# COMPUTE_CLUSTER0_MSMC_ECC_AGGR0 register map
Vendor: Texas Instruments
Peripheral module from a debugger description file (folder J7ES).
Registers are 32-bit, access not given, reset 0x0 unless marked. A register's access mark holds for its fields unless they carry their own. Offsets are as the file gives them; lines under a group give offsets from that group; [hi:lo] are bit positions; {n}, {i} and the like mark numbered series; 'fields as' and 'values as' point back to an identical list; <NAME> marks a mode.

## COMPUTE_CLUSTER0_MSMC_ECC_AGGR0
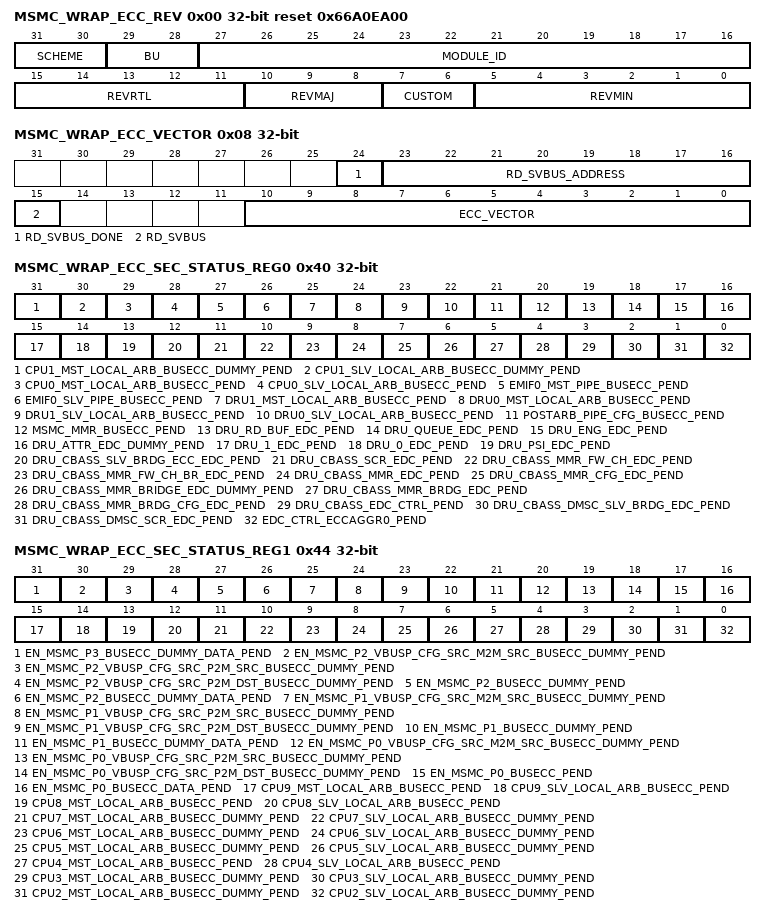
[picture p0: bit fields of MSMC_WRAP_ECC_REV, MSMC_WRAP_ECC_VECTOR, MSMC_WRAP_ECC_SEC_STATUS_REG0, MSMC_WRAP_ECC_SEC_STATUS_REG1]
0x00 MSMC_WRAP_ECC_REV ro reset 0x66A0EA00 — Revision parameters
  [31:30] SCHEME
  [29:28] BU
  [27:16] MODULE_ID
  [15:11] REVRTL — RTL version
  [10:8] REVMAJ — Major version
  [7:6] CUSTOM — Custom version
  [5:0] REVMIN — Minor version
0x08 MSMC_WRAP_ECC_VECTOR — ECC Vector Register
  [24] RD_SVBUS_DONE — Status to indicate if read on serial VBUS is complete, write of any value will clear this bit. (access RW1C)
  [23:16] RD_SVBUS_ADDRESS rw — Read address
  [15] RD_SVBUS — Write 1 to trigger a read on the serial VBUS (access RW1S)
  [10:0] ECC_VECTOR rw — Value written to select the corresponding ECC RAM for control or status
0x0C MSMC_WRAP_ECC_STAT ro reset 0x6C — Misc Status
  [10:0] NUM_RAMS — Indicates the number of RAMS serviced by the ECC aggregator
0x10 MSMC_WRAP_ECC_RESERVED_SVBUS_y rw — Reference other documents that contain the ECC RAM wrapper and EDC controller serial vbus register sets. Offset = 10h + (y * 4h); where y = 0h to 7h
  [31:0] DATA — Serial VBUS register data
0x3C MSMC_WRAP_ECC_SEC_EOI_REG — EOI Register The EOI register is used to re-trigger the pulse interrupt signal to ensure that any nested interrupt events are serviced. The software interrupt handler must write to the EOI register at the end of the current interrupt processing routine, so that new events can re-trigger the pulse interrupt signal again. For level interrupt signals the EOI register is not functional and must not be used.
  [0] EOI_WR — EOI Register (access RW1S)
0x40 MSMC_WRAP_ECC_SEC_STATUS_REG0 — Interrupt Status Register 0
  [31] CPU1_MST_LOCAL_ARB_BUSECC_DUMMY_PEND — Interrupt Pending Status for cpu1_mst_local_arb_busecc_dummy_pend (access RW1S)
  [30] CPU1_SLV_LOCAL_ARB_BUSECC_DUMMY_PEND — Interrupt Pending Status for cpu1_slv_local_arb_busecc_dummy_pend (access RW1S)
  [29] CPU0_MST_LOCAL_ARB_BUSECC_PEND — Interrupt Pending Status for cpu0_mst_local_arb_busecc_pend (access RW1S)
  [28] CPU0_SLV_LOCAL_ARB_BUSECC_PEND — Interrupt Pending Status for cpu0_slv_local_arb_busecc_pend (access RW1S)
  [27] EMIF0_MST_PIPE_BUSECC_PEND — Interrupt Pending Status for emif0_mst_pipe_busecc_pend (access RW1S)
  [26] EMIF0_SLV_PIPE_BUSECC_PEND — Interrupt Pending Status for emif0_slv_pipe_busecc_pend (access RW1S)
  [25] DRU1_MST_LOCAL_ARB_BUSECC_PEND — Interrupt Pending Status for dru1_mst_local_arb_busecc_pend (access RW1S)
  [24] DRU0_MST_LOCAL_ARB_BUSECC_PEND — Interrupt Pending Status for dru0_mst_local_arb_busecc_pend (access RW1S)
  [23] DRU1_SLV_LOCAL_ARB_BUSECC_PEND — Interrupt Pending Status for dru1_slv_local_arb_busecc_pend (access RW1S)
  [22] DRU0_SLV_LOCAL_ARB_BUSECC_PEND — Interrupt Pending Status for dru0_slv_local_arb_busecc_pend (access RW1S)
  [21] POSTARB_PIPE_CFG_BUSECC_PEND — Interrupt Pending Status for postarb_pipe_cfg_busecc_pend (access RW1S)
  [20] MSMC_MMR_BUSECC_PEND — Interrupt Pending Status for msmc_mmr_busecc_pend (access RW1S)
  [19] DRU_RD_BUF_EDC_PEND — Interrupt Pending Status for dru_rd_buf_edc_pend (access RW1S)
  [18] DRU_QUEUE_EDC_PEND — Interrupt Pending Status for dru_queue_edc_pend (access RW1S)
  [17] DRU_ENG_EDC_PEND — Interrupt Pending Status for dru_eng_edc_pend (access RW1S)
  [16] DRU_ATTR_EDC_DUMMY_PEND — Interrupt Pending Status for dru_attr_edc_dummy_pend (access RW1S)
  [15] DRU_1_EDC_PEND — Interrupt Pending Status for dru_1_edc_pend (access RW1S)
  [14] DRU_0_EDC_PEND — Interrupt Pending Status for dru_0_edc_pend (access RW1S)
  [13] DRU_PSI_EDC_PEND — Interrupt Pending Status for dru_psi_edc_pend (access RW1S)
  [12] DRU_CBASS_SLV_BRDG_ECC_EDC_PEND — Interrupt Pending Status for dru_cbass_slv_brdg_ecc_edc_pend (access RW1S)
  [11] DRU_CBASS_SCR_EDC_PEND — Interrupt Pending Status for dru_cbass_scr_edc_pend (access RW1S)
  [10] DRU_CBASS_MMR_FW_CH_EDC_PEND — Interrupt Pending Status for dru_cbass_mmr_fw_ch_edc_pend (access RW1S)
  [9] DRU_CBASS_MMR_FW_CH_BR_EDC_PEND — Interrupt Pending Status for dru_cbass_mmr_fw_ch_br_edc_pend (access RW1S)
  [8] DRU_CBASS_MMR_EDC_PEND — Interrupt Pending Status for dru_cbass_mmr_edc_pend (access RW1S)
  [7] DRU_CBASS_MMR_CFG_EDC_PEND — Interrupt Pending Status for dru_cbass_mmr_cfg_edc_pend (access RW1S)
  [6] DRU_CBASS_MMR_BRIDGE_EDC_DUMMY_PEND — Interrupt Pending Status for dru_cbass_mmr_bridge_edc_dummy_pend (access RW1S)
  [5] DRU_CBASS_MMR_BRDG_EDC_PEND — Interrupt Pending Status for dru_cbass_mmr_brdg_edc_pend (access RW1S)
  [4] DRU_CBASS_MMR_BRDG_CFG_EDC_PEND — Interrupt Pending Status for dru_cbass_mmr_brdg_cfg_edc_pend (access RW1S)
  [3] DRU_CBASS_EDC_CTRL_PEND — Interrupt Pending Status for dru_cbass_edc_ctrl_pend (access RW1S)
  [2] DRU_CBASS_DMSC_SLV_BRDG_EDC_PEND — Interrupt Pending Status for dru_cbass_dmsc_slv_brdg_edc_pend (access RW1S)
  [1] DRU_CBASS_DMSC_SCR_EDC_PEND — Interrupt Pending Status for dru_cbass_dmsc_scr_edc_pend (access RW1S)
  [0] EDC_CTRL_ECCAGGR0_PEND — Interrupt Pending Status for edc_ctrl_eccaggr0_pend (access RW1S)
0x44 MSMC_WRAP_ECC_SEC_STATUS_REG1 — Interrupt Status Register 1
  [31] EN_MSMC_P3_BUSECC_DUMMY_DATA_PEND — Interrupt Pending Status for en_msmc_p3_busecc_dummy_data_pend (access RW1S)
  [30] EN_MSMC_P2_VBUSP_CFG_SRC_M2M_SRC_BUSECC_DUMMY_PEND — Interrupt Pending Status for en_msmc_p2_vbusp_cfg_src_m2m_src_busecc_dummy_pend (access RW1S)
  [29] EN_MSMC_P2_VBUSP_CFG_SRC_P2M_SRC_BUSECC_DUMMY_PEND — Interrupt Pending Status for en_msmc_p2_vbusp_cfg_src_p2m_src_busecc_dummy_pend (access RW1S)
  [28] EN_MSMC_P2_VBUSP_CFG_SRC_P2M_DST_BUSECC_DUMMY_PEND — Interrupt Pending Status for en_msmc_p2_vbusp_cfg_src_p2m_dst_busecc_dummy_pend (access RW1S)
  [27] EN_MSMC_P2_BUSECC_DUMMY_PEND — Interrupt Pending Status for en_msmc_p2_busecc_dummy_pend (access RW1S)
  [26] EN_MSMC_P2_BUSECC_DUMMY_DATA_PEND — Interrupt Pending Status for en_msmc_p2_busecc_dummy_data_pend (access RW1S)
  [25] EN_MSMC_P1_VBUSP_CFG_SRC_M2M_SRC_BUSECC_DUMMY_PEND — Interrupt Pending Status for en_msmc_p1_vbusp_cfg_src_m2m_src_busecc_dummy_pend (access RW1S)
  [24] EN_MSMC_P1_VBUSP_CFG_SRC_P2M_SRC_BUSECC_DUMMY_PEND — Interrupt Pending Status for en_msmc_p1_vbusp_cfg_src_p2m_src_busecc_dummy_pend (access RW1S)
  [23] EN_MSMC_P1_VBUSP_CFG_SRC_P2M_DST_BUSECC_DUMMY_PEND — Interrupt Pending Status for en_msmc_p1_vbusp_cfg_src_p2m_dst_busecc_dummy_pend (access RW1S)
  [22] EN_MSMC_P1_BUSECC_DUMMY_PEND — Interrupt Pending Status for en_msmc_p1_busecc_dummy_pend (access RW1S)
  [21] EN_MSMC_P1_BUSECC_DUMMY_DATA_PEND — Interrupt Pending Status for en_msmc_p1_busecc_dummy_data_pend (access RW1S)
  [20] EN_MSMC_P0_VBUSP_CFG_SRC_M2M_SRC_BUSECC_DUMMY_PEND — Interrupt Pending Status for en_msmc_p0_vbusp_cfg_src_m2m_src_busecc_dummy_pend (access RW1S)
  [19] EN_MSMC_P0_VBUSP_CFG_SRC_P2M_SRC_BUSECC_DUMMY_PEND — Interrupt Pending Status for en_msmc_p0_vbusp_cfg_src_p2m_src_busecc_dummy_pend (access RW1S)
  [18] EN_MSMC_P0_VBUSP_CFG_SRC_P2M_DST_BUSECC_DUMMY_PEND — Interrupt Pending Status for en_msmc_p0_vbusp_cfg_src_p2m_dst_busecc_dummy_pend (access RW1S)
  [17] EN_MSMC_P0_BUSECC_PEND — Interrupt Pending Status for en_msmc_p0_busecc_pend (access RW1S)
  [16] EN_MSMC_P0_BUSECC_DATA_PEND — Interrupt Pending Status for en_msmc_p0_busecc_data_pend (access RW1S)
  [15] CPU9_MST_LOCAL_ARB_BUSECC_PEND — Interrupt Pending Status for cpu9_mst_local_arb_busecc_pend (access RW1S)
  [14] CPU9_SLV_LOCAL_ARB_BUSECC_PEND — Interrupt Pending Status for cpu9_slv_local_arb_busecc_pend (access RW1S)
  [13] CPU8_MST_LOCAL_ARB_BUSECC_PEND — Interrupt Pending Status for cpu8_mst_local_arb_busecc_pend (access RW1S)
  [12] CPU8_SLV_LOCAL_ARB_BUSECC_PEND — Interrupt Pending Status for cpu8_slv_local_arb_busecc_pend (access RW1S)
  [11] CPU7_MST_LOCAL_ARB_BUSECC_DUMMY_PEND — Interrupt Pending Status for cpu7_mst_local_arb_busecc_dummy_pend (access RW1S)
  [10] CPU7_SLV_LOCAL_ARB_BUSECC_DUMMY_PEND — Interrupt Pending Status for cpu7_slv_local_arb_busecc_dummy_pend (access RW1S)
  [9] CPU6_MST_LOCAL_ARB_BUSECC_DUMMY_PEND — Interrupt Pending Status for cpu6_mst_local_arb_busecc_dummy_pend (access RW1S)
  [8] CPU6_SLV_LOCAL_ARB_BUSECC_DUMMY_PEND — Interrupt Pending Status for cpu6_slv_local_arb_busecc_dummy_pend (access RW1S)
  [7] CPU5_MST_LOCAL_ARB_BUSECC_DUMMY_PEND — Interrupt Pending Status for cpu5_mst_local_arb_busecc_dummy_pend (access RW1S)
  [6] CPU5_SLV_LOCAL_ARB_BUSECC_DUMMY_PEND — Interrupt Pending Status for cpu5_slv_local_arb_busecc_dummy_pend (access RW1S)
  [5] CPU4_MST_LOCAL_ARB_BUSECC_PEND — Interrupt Pending Status for cpu4_mst_local_arb_busecc_pend (access RW1S)
  [4] CPU4_SLV_LOCAL_ARB_BUSECC_PEND — Interrupt Pending Status for cpu4_slv_local_arb_busecc_pend (access RW1S)
  [3] CPU3_MST_LOCAL_ARB_BUSECC_DUMMY_PEND — Interrupt Pending Status for cpu3_mst_local_arb_busecc_dummy_pend (access RW1S)
  [2] CPU3_SLV_LOCAL_ARB_BUSECC_DUMMY_PEND — Interrupt Pending Status for cpu3_slv_local_arb_busecc_dummy_pend (access RW1S)
  [1] CPU2_MST_LOCAL_ARB_BUSECC_DUMMY_PEND — Interrupt Pending Status for cpu2_mst_local_arb_busecc_dummy_pend (access RW1S)
  [0] CPU2_SLV_LOCAL_ARB_BUSECC_DUMMY_PEND — Interrupt Pending Status for cpu2_slv_local_arb_busecc_dummy_pend (access RW1S)
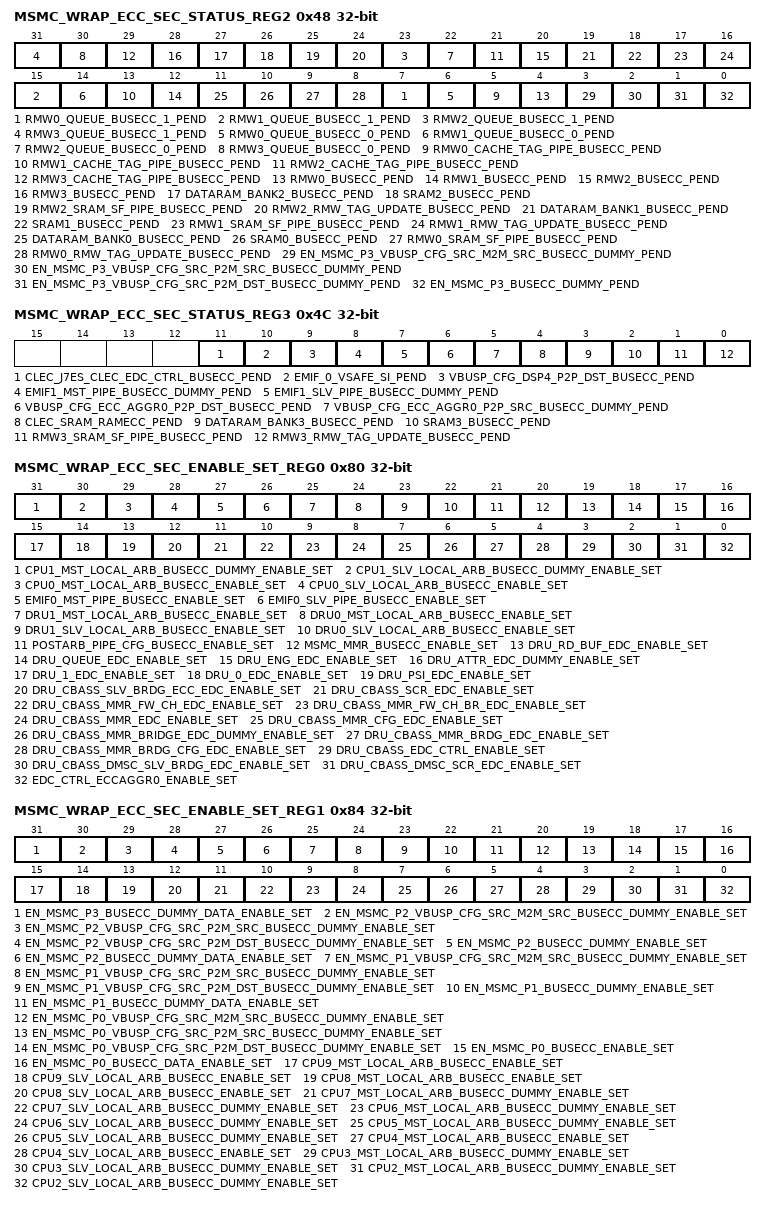
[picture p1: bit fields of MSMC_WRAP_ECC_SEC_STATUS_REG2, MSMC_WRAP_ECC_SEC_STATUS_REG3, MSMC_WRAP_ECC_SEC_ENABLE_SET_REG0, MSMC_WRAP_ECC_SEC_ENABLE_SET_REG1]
0x48 MSMC_WRAP_ECC_SEC_STATUS_REG2 — Interrupt Status Register 2
  [8n+7] RMW{n}_QUEUE_BUSECC_1_PEND (n=0..3) — Interrupt Pending Status for rmw{n}_queue_busecc_1_pend (access RW1S)
  [8n+6] RMW{n}_QUEUE_BUSECC_0_PEND (n=0..3) — Interrupt Pending Status for rmw{n}_queue_busecc_0_pend (access RW1S)
  [8n+5] RMW{n}_CACHE_TAG_PIPE_BUSECC_PEND (n=0..3) — Interrupt Pending Status for rmw{n}_cache_tag_pipe_busecc_pend (access RW1S)
  [8n+4] RMW{n}_BUSECC_PEND (n=0..3) — Interrupt Pending Status for rmw{n}_busecc_pend (access RW1S)
  [27] DATARAM_BANK2_BUSECC_PEND — Interrupt Pending Status for dataram_bank2_busecc_pend (access RW1S)
  [26] SRAM2_BUSECC_PEND — Interrupt Pending Status for sram2_busecc_pend (access RW1S)
  [25] RMW2_SRAM_SF_PIPE_BUSECC_PEND — Interrupt Pending Status for rmw2_sram_sf_pipe_busecc_pend (access RW1S)
  [24] RMW2_RMW_TAG_UPDATE_BUSECC_PEND — Interrupt Pending Status for rmw2_rmw_tag_update_busecc_pend (access RW1S)
  [19] DATARAM_BANK1_BUSECC_PEND — Interrupt Pending Status for dataram_bank1_busecc_pend (access RW1S)
  [18] SRAM1_BUSECC_PEND — Interrupt Pending Status for sram1_busecc_pend (access RW1S)
  [17] RMW1_SRAM_SF_PIPE_BUSECC_PEND — Interrupt Pending Status for rmw1_sram_sf_pipe_busecc_pend (access RW1S)
  [16] RMW1_RMW_TAG_UPDATE_BUSECC_PEND — Interrupt Pending Status for rmw1_rmw_tag_update_busecc_pend (access RW1S)
  [11] DATARAM_BANK0_BUSECC_PEND — Interrupt Pending Status for dataram_bank0_busecc_pend (access RW1S)
  [10] SRAM0_BUSECC_PEND — Interrupt Pending Status for sram0_busecc_pend (access RW1S)
  [9] RMW0_SRAM_SF_PIPE_BUSECC_PEND — Interrupt Pending Status for rmw0_sram_sf_pipe_busecc_pend (access RW1S)
  [8] RMW0_RMW_TAG_UPDATE_BUSECC_PEND — Interrupt Pending Status for rmw0_rmw_tag_update_busecc_pend (access RW1S)
  [3] EN_MSMC_P3_VBUSP_CFG_SRC_M2M_SRC_BUSECC_DUMMY_PEND — Interrupt Pending Status for en_msmc_p3_vbusp_cfg_src_m2m_src_busecc_dummy_pend (access RW1S)
  [2] EN_MSMC_P3_VBUSP_CFG_SRC_P2M_SRC_BUSECC_DUMMY_PEND — Interrupt Pending Status for en_msmc_p3_vbusp_cfg_src_p2m_src_busecc_dummy_pend (access RW1S)
  [1] EN_MSMC_P3_VBUSP_CFG_SRC_P2M_DST_BUSECC_DUMMY_PEND — Interrupt Pending Status for en_msmc_p3_vbusp_cfg_src_p2m_dst_busecc_dummy_pend (access RW1S)
  [0] EN_MSMC_P3_BUSECC_DUMMY_PEND — Interrupt Pending Status for en_msmc_p3_busecc_dummy_pend (access RW1S)
0x4C MSMC_WRAP_ECC_SEC_STATUS_REG3 — Interrupt Status Register 3
  [11] CLEC_J7ES_CLEC_EDC_CTRL_BUSECC_PEND — Interrupt Pending Status for clec_clec_edc_ctrl_busecc_pend (access RW1S)
  [10] EMIF_0_VSAFE_SI_PEND — Interrupt Pending Status for emif_0_vsafe_si_pend (access RW1S)
  [9] VBUSP_CFG_DSP4_P2P_DST_BUSECC_PEND — Interrupt Pending Status for vbusp_cfg_dsp4_p2p_dst_busecc_pend (access RW1S)
  [8] EMIF1_MST_PIPE_BUSECC_DUMMY_PEND — Interrupt Pending Status for emif1_mst_pipe_busecc_dummy_pend (access RW1S)
  [7] EMIF1_SLV_PIPE_BUSECC_DUMMY_PEND — Interrupt Pending Status for emif1_slv_pipe_busecc_dummy_pend (access RW1S)
  [6] VBUSP_CFG_ECC_AGGR0_P2P_DST_BUSECC_PEND — Interrupt Pending Status for vbusp_cfg_ecc_aggr0_p2p_dst_busecc_pend (access RW1S)
  [5] VBUSP_CFG_ECC_AGGR0_P2P_SRC_BUSECC_DUMMY_PEND — Interrupt Pending Status for vbusp_cfg_ecc_aggr0_p2p_src_busecc_dummy_pend (access RW1S)
  [4] CLEC_SRAM_RAMECC_PEND — Interrupt Pending Status for clec_sram_ramecc_pend (access RW1S)
  [3] DATARAM_BANK3_BUSECC_PEND — Interrupt Pending Status for dataram_bank3_busecc_pend (access RW1S)
  [2] SRAM3_BUSECC_PEND — Interrupt Pending Status for sram3_busecc_pend (access RW1S)
  [1] RMW3_SRAM_SF_PIPE_BUSECC_PEND — Interrupt Pending Status for rmw3_sram_sf_pipe_busecc_pend (access RW1S)
  [0] RMW3_RMW_TAG_UPDATE_BUSECC_PEND — Interrupt Pending Status for rmw3_rmw_tag_update_busecc_pend (access RW1S)
0x80 MSMC_WRAP_ECC_SEC_ENABLE_SET_REG0 — Interrupt Enable Set Register 0
  [31] CPU1_MST_LOCAL_ARB_BUSECC_DUMMY_ENABLE_SET — Interrupt Enable Set Register for cpu1_mst_local_arb_busecc_dummy_pend (access RW1S)
  [30] CPU1_SLV_LOCAL_ARB_BUSECC_DUMMY_ENABLE_SET — Interrupt Enable Set Register for cpu1_slv_local_arb_busecc_dummy_pend (access RW1S)
  [29] CPU0_MST_LOCAL_ARB_BUSECC_ENABLE_SET — Interrupt Enable Set Register for cpu0_mst_local_arb_busecc_pend (access RW1S)
  [28] CPU0_SLV_LOCAL_ARB_BUSECC_ENABLE_SET — Interrupt Enable Set Register for cpu0_slv_local_arb_busecc_pend (access RW1S)
  [27] EMIF0_MST_PIPE_BUSECC_ENABLE_SET — Interrupt Enable Set Register for emif0_mst_pipe_busecc_pend (access RW1S)
  [26] EMIF0_SLV_PIPE_BUSECC_ENABLE_SET — Interrupt Enable Set Register for emif0_slv_pipe_busecc_pend (access RW1S)
  [25] DRU1_MST_LOCAL_ARB_BUSECC_ENABLE_SET — Interrupt Enable Set Register for dru1_mst_local_arb_busecc_pend (access RW1S)
  [24] DRU0_MST_LOCAL_ARB_BUSECC_ENABLE_SET — Interrupt Enable Set Register for dru0_mst_local_arb_busecc_pend (access RW1S)
  [23] DRU1_SLV_LOCAL_ARB_BUSECC_ENABLE_SET — Interrupt Enable Set Register for dru1_slv_local_arb_busecc_pend (access RW1S)
  [22] DRU0_SLV_LOCAL_ARB_BUSECC_ENABLE_SET — Interrupt Enable Set Register for dru0_slv_local_arb_busecc_pend (access RW1S)
  [21] POSTARB_PIPE_CFG_BUSECC_ENABLE_SET — Interrupt Enable Set Register for postarb_pipe_cfg_busecc_pend (access RW1S)
  [20] MSMC_MMR_BUSECC_ENABLE_SET — Interrupt Enable Set Register for msmc_mmr_busecc_pend (access RW1S)
  [19] DRU_RD_BUF_EDC_ENABLE_SET — Interrupt Enable Set Register for dru_rd_buf_edc_pend (access RW1S)
  [18] DRU_QUEUE_EDC_ENABLE_SET — Interrupt Enable Set Register for dru_queue_edc_pend (access RW1S)
  [17] DRU_ENG_EDC_ENABLE_SET — Interrupt Enable Set Register for dru_eng_edc_pend (access RW1S)
  [16] DRU_ATTR_EDC_DUMMY_ENABLE_SET — Interrupt Enable Set Register for dru_attr_edc_dummy_pend (access RW1S)
  [15] DRU_1_EDC_ENABLE_SET — Interrupt Enable Set Register for dru_1_edc_pend (access RW1S)
  [14] DRU_0_EDC_ENABLE_SET — Interrupt Enable Set Register for dru_0_edc_pend (access RW1S)
  [13] DRU_PSI_EDC_ENABLE_SET — Interrupt Enable Set Register for dru_psi_edc_pend (access RW1S)
  [12] DRU_CBASS_SLV_BRDG_ECC_EDC_ENABLE_SET — Interrupt Enable Set Register for dru_cbass_slv_brdg_ecc_edc_pend (access RW1S)
  [11] DRU_CBASS_SCR_EDC_ENABLE_SET — Interrupt Enable Set Register for dru_cbass_scr_edc_pend (access RW1S)
  [10] DRU_CBASS_MMR_FW_CH_EDC_ENABLE_SET — Interrupt Enable Set Register for dru_cbass_mmr_fw_ch_edc_pend (access RW1S)
  [9] DRU_CBASS_MMR_FW_CH_BR_EDC_ENABLE_SET — Interrupt Enable Set Register for dru_cbass_mmr_fw_ch_br_edc_pend (access RW1S)
  [8] DRU_CBASS_MMR_EDC_ENABLE_SET — Interrupt Enable Set Register for dru_cbass_mmr_edc_pend (access RW1S)
  [7] DRU_CBASS_MMR_CFG_EDC_ENABLE_SET — Interrupt Enable Set Register for dru_cbass_mmr_cfg_edc_pend (access RW1S)
  [6] DRU_CBASS_MMR_BRIDGE_EDC_DUMMY_ENABLE_SET — Interrupt Enable Set Register for dru_cbass_mmr_bridge_edc_dummy_pend (access RW1S)
  [5] DRU_CBASS_MMR_BRDG_EDC_ENABLE_SET — Interrupt Enable Set Register for dru_cbass_mmr_brdg_edc_pend (access RW1S)
  [4] DRU_CBASS_MMR_BRDG_CFG_EDC_ENABLE_SET — Interrupt Enable Set Register for dru_cbass_mmr_brdg_cfg_edc_pend (access RW1S)
  [3] DRU_CBASS_EDC_CTRL_ENABLE_SET — Interrupt Enable Set Register for dru_cbass_edc_ctrl_pend (access RW1S)
  [2] DRU_CBASS_DMSC_SLV_BRDG_EDC_ENABLE_SET — Interrupt Enable Set Register for dru_cbass_dmsc_slv_brdg_edc_pend (access RW1S)
  [1] DRU_CBASS_DMSC_SCR_EDC_ENABLE_SET — Interrupt Enable Set Register for dru_cbass_dmsc_scr_edc_pend (access RW1S)
  [0] EDC_CTRL_ECCAGGR0_ENABLE_SET — Interrupt Enable Set Register for edc_ctrl_eccaggr0_pend (access RW1S)
0x84 MSMC_WRAP_ECC_SEC_ENABLE_SET_REG1 — Interrupt Enable Set Register 1
  [31] EN_MSMC_P3_BUSECC_DUMMY_DATA_ENABLE_SET — Interrupt Enable Set Register for en_msmc_p3_busecc_dummy_data_pend (access RW1S)
  [30] EN_MSMC_P2_VBUSP_CFG_SRC_M2M_SRC_BUSECC_DUMMY_ENABLE_SET — Interrupt Enable Set Register for en_msmc_p2_vbusp_cfg_src_m2m_src_busecc_dummy_pend (access RW1S)
  [29] EN_MSMC_P2_VBUSP_CFG_SRC_P2M_SRC_BUSECC_DUMMY_ENABLE_SET — Interrupt Enable Set Register for en_msmc_p2_vbusp_cfg_src_p2m_src_busecc_dummy_pend (access RW1S)
  [28] EN_MSMC_P2_VBUSP_CFG_SRC_P2M_DST_BUSECC_DUMMY_ENABLE_SET — Interrupt Enable Set Register for en_msmc_p2_vbusp_cfg_src_p2m_dst_busecc_dummy_pend (access RW1S)
  [27] EN_MSMC_P2_BUSECC_DUMMY_ENABLE_SET — Interrupt Enable Set Register for en_msmc_p2_busecc_dummy_pend (access RW1S)
  [26] EN_MSMC_P2_BUSECC_DUMMY_DATA_ENABLE_SET — Interrupt Enable Set Register for en_msmc_p2_busecc_dummy_data_pend (access RW1S)
  [25] EN_MSMC_P1_VBUSP_CFG_SRC_M2M_SRC_BUSECC_DUMMY_ENABLE_SET — Interrupt Enable Set Register for en_msmc_p1_vbusp_cfg_src_m2m_src_busecc_dummy_pend (access RW1S)
  [24] EN_MSMC_P1_VBUSP_CFG_SRC_P2M_SRC_BUSECC_DUMMY_ENABLE_SET — Interrupt Enable Set Register for en_msmc_p1_vbusp_cfg_src_p2m_src_busecc_dummy_pend (access RW1S)
  [23] EN_MSMC_P1_VBUSP_CFG_SRC_P2M_DST_BUSECC_DUMMY_ENABLE_SET — Interrupt Enable Set Register for en_msmc_p1_vbusp_cfg_src_p2m_dst_busecc_dummy_pend (access RW1S)
  [22] EN_MSMC_P1_BUSECC_DUMMY_ENABLE_SET — Interrupt Enable Set Register for en_msmc_p1_busecc_dummy_pend (access RW1S)
  [21] EN_MSMC_P1_BUSECC_DUMMY_DATA_ENABLE_SET — Interrupt Enable Set Register for en_msmc_p1_busecc_dummy_data_pend (access RW1S)
  [20] EN_MSMC_P0_VBUSP_CFG_SRC_M2M_SRC_BUSECC_DUMMY_ENABLE_SET — Interrupt Enable Set Register for en_msmc_p0_vbusp_cfg_src_m2m_src_busecc_dummy_pend (access RW1S)
  [19] EN_MSMC_P0_VBUSP_CFG_SRC_P2M_SRC_BUSECC_DUMMY_ENABLE_SET — Interrupt Enable Set Register for en_msmc_p0_vbusp_cfg_src_p2m_src_busecc_dummy_pend (access RW1S)
  [18] EN_MSMC_P0_VBUSP_CFG_SRC_P2M_DST_BUSECC_DUMMY_ENABLE_SET — Interrupt Enable Set Register for en_msmc_p0_vbusp_cfg_src_p2m_dst_busecc_dummy_pend (access RW1S)
  [17] EN_MSMC_P0_BUSECC_ENABLE_SET — Interrupt Enable Set Register for en_msmc_p0_busecc_pend (access RW1S)
  [16] EN_MSMC_P0_BUSECC_DATA_ENABLE_SET — Interrupt Enable Set Register for en_msmc_p0_busecc_data_pend (access RW1S)
  [15] CPU9_MST_LOCAL_ARB_BUSECC_ENABLE_SET — Interrupt Enable Set Register for cpu9_mst_local_arb_busecc_pend (access RW1S)
  [14] CPU9_SLV_LOCAL_ARB_BUSECC_ENABLE_SET — Interrupt Enable Set Register for cpu9_slv_local_arb_busecc_pend (access RW1S)
  [13] CPU8_MST_LOCAL_ARB_BUSECC_ENABLE_SET — Interrupt Enable Set Register for cpu8_mst_local_arb_busecc_pend (access RW1S)
  [12] CPU8_SLV_LOCAL_ARB_BUSECC_ENABLE_SET — Interrupt Enable Set Register for cpu8_slv_local_arb_busecc_pend (access RW1S)
  [11] CPU7_MST_LOCAL_ARB_BUSECC_DUMMY_ENABLE_SET — Interrupt Enable Set Register for cpu7_mst_local_arb_busecc_dummy_pend (access RW1S)
  [10] CPU7_SLV_LOCAL_ARB_BUSECC_DUMMY_ENABLE_SET — Interrupt Enable Set Register for cpu7_slv_local_arb_busecc_dummy_pend (access RW1S)
  [9] CPU6_MST_LOCAL_ARB_BUSECC_DUMMY_ENABLE_SET — Interrupt Enable Set Register for cpu6_mst_local_arb_busecc_dummy_pend (access RW1S)
  [8] CPU6_SLV_LOCAL_ARB_BUSECC_DUMMY_ENABLE_SET — Interrupt Enable Set Register for cpu6_slv_local_arb_busecc_dummy_pend (access RW1S)
  [7] CPU5_MST_LOCAL_ARB_BUSECC_DUMMY_ENABLE_SET — Interrupt Enable Set Register for cpu5_mst_local_arb_busecc_dummy_pend (access RW1S)
  [6] CPU5_SLV_LOCAL_ARB_BUSECC_DUMMY_ENABLE_SET — Interrupt Enable Set Register for cpu5_slv_local_arb_busecc_dummy_pend (access RW1S)
  [5] CPU4_MST_LOCAL_ARB_BUSECC_ENABLE_SET — Interrupt Enable Set Register for cpu4_mst_local_arb_busecc_pend (access RW1S)
  [4] CPU4_SLV_LOCAL_ARB_BUSECC_ENABLE_SET — Interrupt Enable Set Register for cpu4_slv_local_arb_busecc_pend (access RW1S)
  [3] CPU3_MST_LOCAL_ARB_BUSECC_DUMMY_ENABLE_SET — Interrupt Enable Set Register for cpu3_mst_local_arb_busecc_dummy_pend (access RW1S)
  [2] CPU3_SLV_LOCAL_ARB_BUSECC_DUMMY_ENABLE_SET — Interrupt Enable Set Register for cpu3_slv_local_arb_busecc_dummy_pend (access RW1S)
  [1] CPU2_MST_LOCAL_ARB_BUSECC_DUMMY_ENABLE_SET — Interrupt Enable Set Register for cpu2_mst_local_arb_busecc_dummy_pend (access RW1S)
  [0] CPU2_SLV_LOCAL_ARB_BUSECC_DUMMY_ENABLE_SET — Interrupt Enable Set Register for cpu2_slv_local_arb_busecc_dummy_pend (access RW1S)
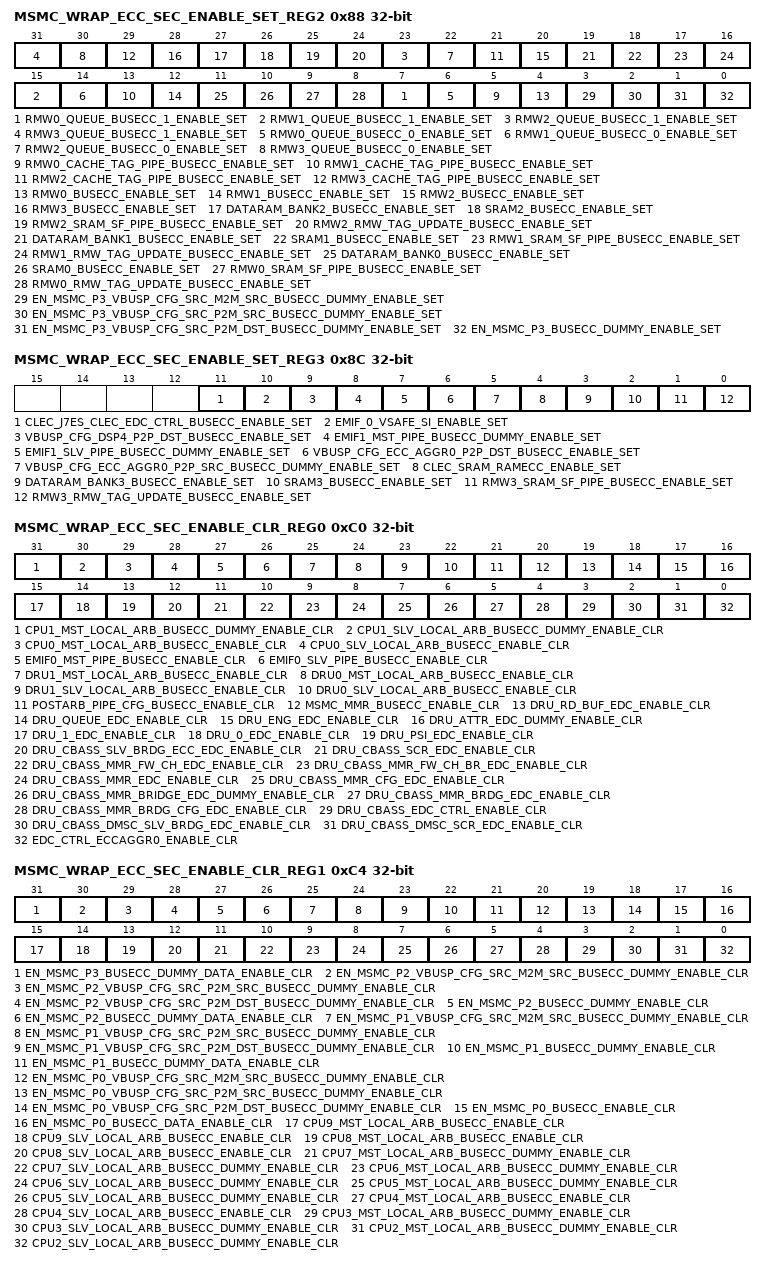
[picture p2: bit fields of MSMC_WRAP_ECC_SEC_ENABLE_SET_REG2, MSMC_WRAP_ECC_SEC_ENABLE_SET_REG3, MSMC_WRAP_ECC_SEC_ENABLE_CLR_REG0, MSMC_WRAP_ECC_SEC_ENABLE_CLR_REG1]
0x88 MSMC_WRAP_ECC_SEC_ENABLE_SET_REG2 — Interrupt Enable Set Register 2
  [8n+7] RMW{n}_QUEUE_BUSECC_1_ENABLE_SET (n=0..3) — Interrupt Enable Set Register for rmw{n}_queue_busecc_1_pend (access RW1S)
  [8n+6] RMW{n}_QUEUE_BUSECC_0_ENABLE_SET (n=0..3) — Interrupt Enable Set Register for rmw{n}_queue_busecc_0_pend (access RW1S)
  [8n+5] RMW{n}_CACHE_TAG_PIPE_BUSECC_ENABLE_SET (n=0..3) — Interrupt Enable Set Register for rmw{n}_cache_tag_pipe_busecc_pend (access RW1S)
  [8n+4] RMW{n}_BUSECC_ENABLE_SET (n=0..3) — Interrupt Enable Set Register for rmw{n}_busecc_pend (access RW1S)
  [27] DATARAM_BANK2_BUSECC_ENABLE_SET — Interrupt Enable Set Register for dataram_bank2_busecc_pend (access RW1S)
  [26] SRAM2_BUSECC_ENABLE_SET — Interrupt Enable Set Register for sram2_busecc_pend (access RW1S)
  [25] RMW2_SRAM_SF_PIPE_BUSECC_ENABLE_SET — Interrupt Enable Set Register for rmw2_sram_sf_pipe_busecc_pend (access RW1S)
  [24] RMW2_RMW_TAG_UPDATE_BUSECC_ENABLE_SET — Interrupt Enable Set Register for rmw2_rmw_tag_update_busecc_pend (access RW1S)
  [19] DATARAM_BANK1_BUSECC_ENABLE_SET — Interrupt Enable Set Register for dataram_bank1_busecc_pend (access RW1S)
  [18] SRAM1_BUSECC_ENABLE_SET — Interrupt Enable Set Register for sram1_busecc_pend (access RW1S)
  [17] RMW1_SRAM_SF_PIPE_BUSECC_ENABLE_SET — Interrupt Enable Set Register for rmw1_sram_sf_pipe_busecc_pend (access RW1S)
  [16] RMW1_RMW_TAG_UPDATE_BUSECC_ENABLE_SET — Interrupt Enable Set Register for rmw1_rmw_tag_update_busecc_pend (access RW1S)
  [11] DATARAM_BANK0_BUSECC_ENABLE_SET — Interrupt Enable Set Register for dataram_bank0_busecc_pend (access RW1S)
  [10] SRAM0_BUSECC_ENABLE_SET — Interrupt Enable Set Register for sram0_busecc_pend (access RW1S)
  [9] RMW0_SRAM_SF_PIPE_BUSECC_ENABLE_SET — Interrupt Enable Set Register for rmw0_sram_sf_pipe_busecc_pend (access RW1S)
  [8] RMW0_RMW_TAG_UPDATE_BUSECC_ENABLE_SET — Interrupt Enable Set Register for rmw0_rmw_tag_update_busecc_pend (access RW1S)
  [3] EN_MSMC_P3_VBUSP_CFG_SRC_M2M_SRC_BUSECC_DUMMY_ENABLE_SET — Interrupt Enable Set Register for en_msmc_p3_vbusp_cfg_src_m2m_src_busecc_dummy_pend (access RW1S)
  [2] EN_MSMC_P3_VBUSP_CFG_SRC_P2M_SRC_BUSECC_DUMMY_ENABLE_SET — Interrupt Enable Set Register for en_msmc_p3_vbusp_cfg_src_p2m_src_busecc_dummy_pend (access RW1S)
  [1] EN_MSMC_P3_VBUSP_CFG_SRC_P2M_DST_BUSECC_DUMMY_ENABLE_SET — Interrupt Enable Set Register for en_msmc_p3_vbusp_cfg_src_p2m_dst_busecc_dummy_pend (access RW1S)
  [0] EN_MSMC_P3_BUSECC_DUMMY_ENABLE_SET — Interrupt Enable Set Register for en_msmc_p3_busecc_dummy_pend (access RW1S)
0x8C MSMC_WRAP_ECC_SEC_ENABLE_SET_REG3 — Interrupt Enable Set Register 3
  [11] CLEC_J7ES_CLEC_EDC_CTRL_BUSECC_ENABLE_SET — Interrupt Enable Set Register for clec_clec_edc_ctrl_busecc_pend (access RW1S)
  [10] EMIF_0_VSAFE_SI_ENABLE_SET — Interrupt Enable Set Register for emif_0_vsafe_si_pend (access RW1S)
  [9] VBUSP_CFG_DSP4_P2P_DST_BUSECC_ENABLE_SET — Interrupt Enable Set Register for vbusp_cfg_dsp4_p2p_dst_busecc_pend (access RW1S)
  [8] EMIF1_MST_PIPE_BUSECC_DUMMY_ENABLE_SET — Interrupt Enable Set Register for emif1_mst_pipe_busecc_dummy_pend (access RW1S)
  [7] EMIF1_SLV_PIPE_BUSECC_DUMMY_ENABLE_SET — Interrupt Enable Set Register for emif1_slv_pipe_busecc_dummy_pend (access RW1S)
  [6] VBUSP_CFG_ECC_AGGR0_P2P_DST_BUSECC_ENABLE_SET — Interrupt Enable Set Register for vbusp_cfg_ecc_aggr0_p2p_dst_busecc_pend (access RW1S)
  [5] VBUSP_CFG_ECC_AGGR0_P2P_SRC_BUSECC_DUMMY_ENABLE_SET — Interrupt Enable Set Register for vbusp_cfg_ecc_aggr0_p2p_src_busecc_dummy_pend (access RW1S)
  [4] CLEC_SRAM_RAMECC_ENABLE_SET — Interrupt Enable Set Register for clec_sram_ramecc_pend (access RW1S)
  [3] DATARAM_BANK3_BUSECC_ENABLE_SET — Interrupt Enable Set Register for dataram_bank3_busecc_pend (access RW1S)
  [2] SRAM3_BUSECC_ENABLE_SET — Interrupt Enable Set Register for sram3_busecc_pend (access RW1S)
  [1] RMW3_SRAM_SF_PIPE_BUSECC_ENABLE_SET — Interrupt Enable Set Register for rmw3_sram_sf_pipe_busecc_pend (access RW1S)
  [0] RMW3_RMW_TAG_UPDATE_BUSECC_ENABLE_SET — Interrupt Enable Set Register for rmw3_rmw_tag_update_busecc_pend (access RW1S)
0xC0 MSMC_WRAP_ECC_SEC_ENABLE_CLR_REG0 — Interrupt Enable Clear Register 0
  [31] CPU1_MST_LOCAL_ARB_BUSECC_DUMMY_ENABLE_CLR — Interrupt Enable Clear Register for cpu1_mst_local_arb_busecc_dummy_pend (access RW1C)
  [30] CPU1_SLV_LOCAL_ARB_BUSECC_DUMMY_ENABLE_CLR — Interrupt Enable Clear Register for cpu1_slv_local_arb_busecc_dummy_pend (access RW1C)
  [29] CPU0_MST_LOCAL_ARB_BUSECC_ENABLE_CLR — Interrupt Enable Clear Register for cpu0_mst_local_arb_busecc_pend (access RW1C)
  [28] CPU0_SLV_LOCAL_ARB_BUSECC_ENABLE_CLR — Interrupt Enable Clear Register for cpu0_slv_local_arb_busecc_pend (access RW1C)
  [27] EMIF0_MST_PIPE_BUSECC_ENABLE_CLR — Interrupt Enable Clear Register for emif0_mst_pipe_busecc_pend (access RW1C)
  [26] EMIF0_SLV_PIPE_BUSECC_ENABLE_CLR — Interrupt Enable Clear Register for emif0_slv_pipe_busecc_pend (access RW1C)
  [25] DRU1_MST_LOCAL_ARB_BUSECC_ENABLE_CLR — Interrupt Enable Clear Register for dru1_mst_local_arb_busecc_pend (access RW1C)
  [24] DRU0_MST_LOCAL_ARB_BUSECC_ENABLE_CLR — Interrupt Enable Clear Register for dru0_mst_local_arb_busecc_pend (access RW1C)
  [23] DRU1_SLV_LOCAL_ARB_BUSECC_ENABLE_CLR — Interrupt Enable Clear Register for dru1_slv_local_arb_busecc_pend (access RW1C)
  [22] DRU0_SLV_LOCAL_ARB_BUSECC_ENABLE_CLR — Interrupt Enable Clear Register for dru0_slv_local_arb_busecc_pend (access RW1C)
  [21] POSTARB_PIPE_CFG_BUSECC_ENABLE_CLR — Interrupt Enable Clear Register for postarb_pipe_cfg_busecc_pend (access RW1C)
  [20] MSMC_MMR_BUSECC_ENABLE_CLR — Interrupt Enable Clear Register for msmc_mmr_busecc_pend (access RW1C)
  [19] DRU_RD_BUF_EDC_ENABLE_CLR — Interrupt Enable Clear Register for dru_rd_buf_edc_pend (access RW1C)
  [18] DRU_QUEUE_EDC_ENABLE_CLR — Interrupt Enable Clear Register for dru_queue_edc_pend (access RW1C)
  [17] DRU_ENG_EDC_ENABLE_CLR — Interrupt Enable Clear Register for dru_eng_edc_pend (access RW1C)
  [16] DRU_ATTR_EDC_DUMMY_ENABLE_CLR — Interrupt Enable Clear Register for dru_attr_edc_dummy_pend (access RW1C)
  [15] DRU_1_EDC_ENABLE_CLR — Interrupt Enable Clear Register for dru_1_edc_pend (access RW1C)
  [14] DRU_0_EDC_ENABLE_CLR — Interrupt Enable Clear Register for dru_0_edc_pend (access RW1C)
  [13] DRU_PSI_EDC_ENABLE_CLR — Interrupt Enable Clear Register for dru_psi_edc_pend (access RW1C)
  [12] DRU_CBASS_SLV_BRDG_ECC_EDC_ENABLE_CLR — Interrupt Enable Clear Register for dru_cbass_slv_brdg_ecc_edc_pend (access RW1C)
  [11] DRU_CBASS_SCR_EDC_ENABLE_CLR — Interrupt Enable Clear Register for dru_cbass_scr_edc_pend (access RW1C)
  [10] DRU_CBASS_MMR_FW_CH_EDC_ENABLE_CLR — Interrupt Enable Clear Register for dru_cbass_mmr_fw_ch_edc_pend (access RW1C)
  [9] DRU_CBASS_MMR_FW_CH_BR_EDC_ENABLE_CLR — Interrupt Enable Clear Register for dru_cbass_mmr_fw_ch_br_edc_pend (access RW1C)
  [8] DRU_CBASS_MMR_EDC_ENABLE_CLR — Interrupt Enable Clear Register for dru_cbass_mmr_edc_pend (access RW1C)
  [7] DRU_CBASS_MMR_CFG_EDC_ENABLE_CLR — Interrupt Enable Clear Register for dru_cbass_mmr_cfg_edc_pend (access RW1C)
  [6] DRU_CBASS_MMR_BRIDGE_EDC_DUMMY_ENABLE_CLR — Interrupt Enable Clear Register for dru_cbass_mmr_bridge_edc_dummy_pend (access RW1C)
  [5] DRU_CBASS_MMR_BRDG_EDC_ENABLE_CLR — Interrupt Enable Clear Register for dru_cbass_mmr_brdg_edc_pend (access RW1C)
  [4] DRU_CBASS_MMR_BRDG_CFG_EDC_ENABLE_CLR — Interrupt Enable Clear Register for dru_cbass_mmr_brdg_cfg_edc_pend (access RW1C)
  [3] DRU_CBASS_EDC_CTRL_ENABLE_CLR — Interrupt Enable Clear Register for dru_cbass_edc_ctrl_pend (access RW1C)
  [2] DRU_CBASS_DMSC_SLV_BRDG_EDC_ENABLE_CLR — Interrupt Enable Clear Register for dru_cbass_dmsc_slv_brdg_edc_pend (access RW1C)
  [1] DRU_CBASS_DMSC_SCR_EDC_ENABLE_CLR — Interrupt Enable Clear Register for dru_cbass_dmsc_scr_edc_pend (access RW1C)
  [0] EDC_CTRL_ECCAGGR0_ENABLE_CLR — Interrupt Enable Clear Register for edc_ctrl_eccaggr0_pend (access RW1C)
0xC4 MSMC_WRAP_ECC_SEC_ENABLE_CLR_REG1 — Interrupt Enable Clear Register 1
  [31] EN_MSMC_P3_BUSECC_DUMMY_DATA_ENABLE_CLR — Interrupt Enable Clear Register for en_msmc_p3_busecc_dummy_data_pend (access RW1C)
  [30] EN_MSMC_P2_VBUSP_CFG_SRC_M2M_SRC_BUSECC_DUMMY_ENABLE_CLR — Interrupt Enable Clear Register for en_msmc_p2_vbusp_cfg_src_m2m_src_busecc_dummy_pend (access RW1C)
  [29] EN_MSMC_P2_VBUSP_CFG_SRC_P2M_SRC_BUSECC_DUMMY_ENABLE_CLR — Interrupt Enable Clear Register for en_msmc_p2_vbusp_cfg_src_p2m_src_busecc_dummy_pend (access RW1C)
  [28] EN_MSMC_P2_VBUSP_CFG_SRC_P2M_DST_BUSECC_DUMMY_ENABLE_CLR — Interrupt Enable Clear Register for en_msmc_p2_vbusp_cfg_src_p2m_dst_busecc_dummy_pend (access RW1C)
  [27] EN_MSMC_P2_BUSECC_DUMMY_ENABLE_CLR — Interrupt Enable Clear Register for en_msmc_p2_busecc_dummy_pend (access RW1C)
  [26] EN_MSMC_P2_BUSECC_DUMMY_DATA_ENABLE_CLR — Interrupt Enable Clear Register for en_msmc_p2_busecc_dummy_data_pend (access RW1C)
  [25] EN_MSMC_P1_VBUSP_CFG_SRC_M2M_SRC_BUSECC_DUMMY_ENABLE_CLR — Interrupt Enable Clear Register for en_msmc_p1_vbusp_cfg_src_m2m_src_busecc_dummy_pend (access RW1C)
  [24] EN_MSMC_P1_VBUSP_CFG_SRC_P2M_SRC_BUSECC_DUMMY_ENABLE_CLR — Interrupt Enable Clear Register for en_msmc_p1_vbusp_cfg_src_p2m_src_busecc_dummy_pend (access RW1C)
  [23] EN_MSMC_P1_VBUSP_CFG_SRC_P2M_DST_BUSECC_DUMMY_ENABLE_CLR — Interrupt Enable Clear Register for en_msmc_p1_vbusp_cfg_src_p2m_dst_busecc_dummy_pend (access RW1C)
  [22] EN_MSMC_P1_BUSECC_DUMMY_ENABLE_CLR — Interrupt Enable Clear Register for en_msmc_p1_busecc_dummy_pend (access RW1C)
  [21] EN_MSMC_P1_BUSECC_DUMMY_DATA_ENABLE_CLR — Interrupt Enable Clear Register for en_msmc_p1_busecc_dummy_data_pend (access RW1C)
  [20] EN_MSMC_P0_VBUSP_CFG_SRC_M2M_SRC_BUSECC_DUMMY_ENABLE_CLR — Interrupt Enable Clear Register for en_msmc_p0_vbusp_cfg_src_m2m_src_busecc_dummy_pend (access RW1C)
  [19] EN_MSMC_P0_VBUSP_CFG_SRC_P2M_SRC_BUSECC_DUMMY_ENABLE_CLR — Interrupt Enable Clear Register for en_msmc_p0_vbusp_cfg_src_p2m_src_busecc_dummy_pend (access RW1C)
  [18] EN_MSMC_P0_VBUSP_CFG_SRC_P2M_DST_BUSECC_DUMMY_ENABLE_CLR — Interrupt Enable Clear Register for en_msmc_p0_vbusp_cfg_src_p2m_dst_busecc_dummy_pend (access RW1C)
  [17] EN_MSMC_P0_BUSECC_ENABLE_CLR — Interrupt Enable Clear Register for en_msmc_p0_busecc_pend (access RW1C)
  [16] EN_MSMC_P0_BUSECC_DATA_ENABLE_CLR — Interrupt Enable Clear Register for en_msmc_p0_busecc_data_pend (access RW1C)
  [15] CPU9_MST_LOCAL_ARB_BUSECC_ENABLE_CLR — Interrupt Enable Clear Register for cpu9_mst_local_arb_busecc_pend (access RW1C)
  [14] CPU9_SLV_LOCAL_ARB_BUSECC_ENABLE_CLR — Interrupt Enable Clear Register for cpu9_slv_local_arb_busecc_pend (access RW1C)
  [13] CPU8_MST_LOCAL_ARB_BUSECC_ENABLE_CLR — Interrupt Enable Clear Register for cpu8_mst_local_arb_busecc_pend (access RW1C)
  [12] CPU8_SLV_LOCAL_ARB_BUSECC_ENABLE_CLR — Interrupt Enable Clear Register for cpu8_slv_local_arb_busecc_pend (access RW1C)
  [11] CPU7_MST_LOCAL_ARB_BUSECC_DUMMY_ENABLE_CLR — Interrupt Enable Clear Register for cpu7_mst_local_arb_busecc_dummy_pend (access RW1C)
  [10] CPU7_SLV_LOCAL_ARB_BUSECC_DUMMY_ENABLE_CLR — Interrupt Enable Clear Register for cpu7_slv_local_arb_busecc_dummy_pend (access RW1C)
  [9] CPU6_MST_LOCAL_ARB_BUSECC_DUMMY_ENABLE_CLR — Interrupt Enable Clear Register for cpu6_mst_local_arb_busecc_dummy_pend (access RW1C)
  [8] CPU6_SLV_LOCAL_ARB_BUSECC_DUMMY_ENABLE_CLR — Interrupt Enable Clear Register for cpu6_slv_local_arb_busecc_dummy_pend (access RW1C)
  [7] CPU5_MST_LOCAL_ARB_BUSECC_DUMMY_ENABLE_CLR — Interrupt Enable Clear Register for cpu5_mst_local_arb_busecc_dummy_pend (access RW1C)
  [6] CPU5_SLV_LOCAL_ARB_BUSECC_DUMMY_ENABLE_CLR — Interrupt Enable Clear Register for cpu5_slv_local_arb_busecc_dummy_pend (access RW1C)
  [5] CPU4_MST_LOCAL_ARB_BUSECC_ENABLE_CLR — Interrupt Enable Clear Register for cpu4_mst_local_arb_busecc_pend (access RW1C)
  [4] CPU4_SLV_LOCAL_ARB_BUSECC_ENABLE_CLR — Interrupt Enable Clear Register for cpu4_slv_local_arb_busecc_pend (access RW1C)
  [3] CPU3_MST_LOCAL_ARB_BUSECC_DUMMY_ENABLE_CLR — Interrupt Enable Clear Register for cpu3_mst_local_arb_busecc_dummy_pend (access RW1C)
  [2] CPU3_SLV_LOCAL_ARB_BUSECC_DUMMY_ENABLE_CLR — Interrupt Enable Clear Register for cpu3_slv_local_arb_busecc_dummy_pend (access RW1C)
  [1] CPU2_MST_LOCAL_ARB_BUSECC_DUMMY_ENABLE_CLR — Interrupt Enable Clear Register for cpu2_mst_local_arb_busecc_dummy_pend (access RW1C)
  [0] CPU2_SLV_LOCAL_ARB_BUSECC_DUMMY_ENABLE_CLR — Interrupt Enable Clear Register for cpu2_slv_local_arb_busecc_dummy_pend (access RW1C)
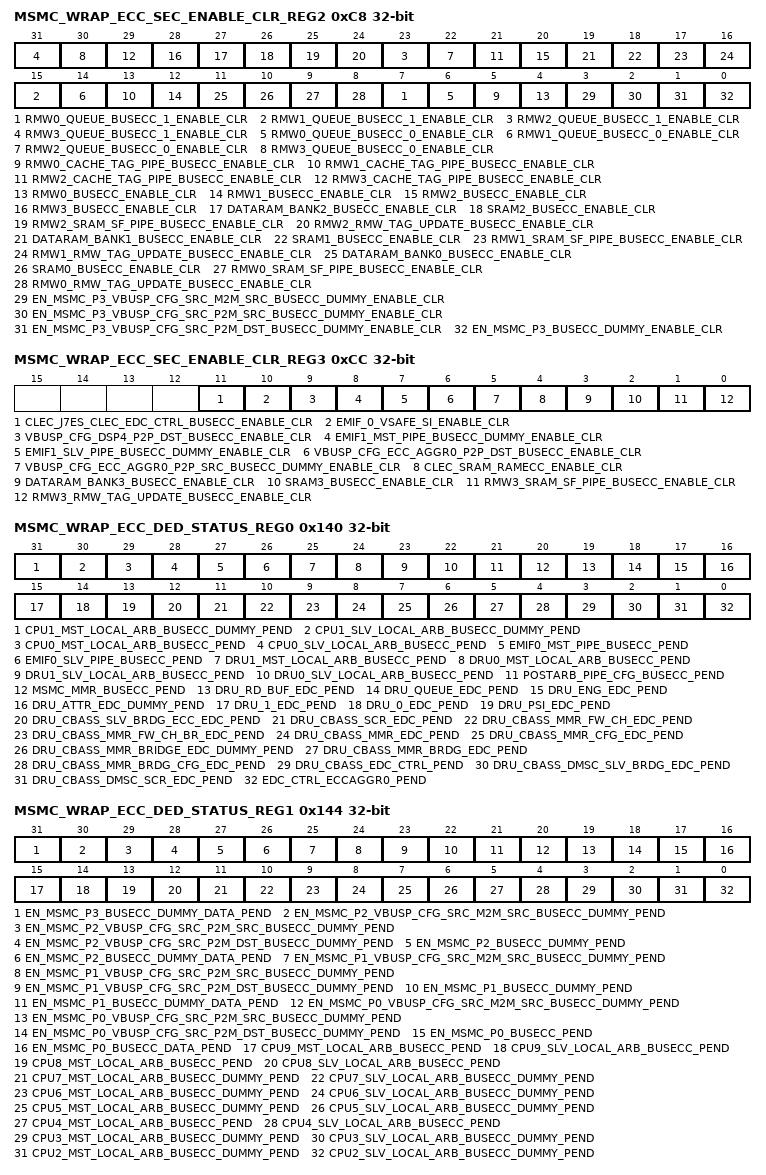
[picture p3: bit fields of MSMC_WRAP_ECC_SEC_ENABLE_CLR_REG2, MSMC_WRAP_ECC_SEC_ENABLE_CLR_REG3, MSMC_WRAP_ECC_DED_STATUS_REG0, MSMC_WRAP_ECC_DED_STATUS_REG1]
0xC8 MSMC_WRAP_ECC_SEC_ENABLE_CLR_REG2 — Interrupt Enable Clear Register 2
  [8n+7] RMW{n}_QUEUE_BUSECC_1_ENABLE_CLR (n=0..3) — Interrupt Enable Clear Register for rmw{n}_queue_busecc_1_pend (access RW1C)
  [8n+6] RMW{n}_QUEUE_BUSECC_0_ENABLE_CLR (n=0..3) — Interrupt Enable Clear Register for rmw{n}_queue_busecc_0_pend (access RW1C)
  [8n+5] RMW{n}_CACHE_TAG_PIPE_BUSECC_ENABLE_CLR (n=0..3) — Interrupt Enable Clear Register for rmw{n}_cache_tag_pipe_busecc_pend (access RW1C)
  [8n+4] RMW{n}_BUSECC_ENABLE_CLR (n=0..3) — Interrupt Enable Clear Register for rmw{n}_busecc_pend (access RW1C)
  [27] DATARAM_BANK2_BUSECC_ENABLE_CLR — Interrupt Enable Clear Register for dataram_bank2_busecc_pend (access RW1C)
  [26] SRAM2_BUSECC_ENABLE_CLR — Interrupt Enable Clear Register for sram2_busecc_pend (access RW1C)
  [25] RMW2_SRAM_SF_PIPE_BUSECC_ENABLE_CLR — Interrupt Enable Clear Register for rmw2_sram_sf_pipe_busecc_pend (access RW1C)
  [24] RMW2_RMW_TAG_UPDATE_BUSECC_ENABLE_CLR — Interrupt Enable Clear Register for rmw2_rmw_tag_update_busecc_pend (access RW1C)
  [19] DATARAM_BANK1_BUSECC_ENABLE_CLR — Interrupt Enable Clear Register for dataram_bank1_busecc_pend (access RW1C)
  [18] SRAM1_BUSECC_ENABLE_CLR — Interrupt Enable Clear Register for sram1_busecc_pend (access RW1C)
  [17] RMW1_SRAM_SF_PIPE_BUSECC_ENABLE_CLR — Interrupt Enable Clear Register for rmw1_sram_sf_pipe_busecc_pend (access RW1C)
  [16] RMW1_RMW_TAG_UPDATE_BUSECC_ENABLE_CLR — Interrupt Enable Clear Register for rmw1_rmw_tag_update_busecc_pend (access RW1C)
  [11] DATARAM_BANK0_BUSECC_ENABLE_CLR — Interrupt Enable Clear Register for dataram_bank0_busecc_pend (access RW1C)
  [10] SRAM0_BUSECC_ENABLE_CLR — Interrupt Enable Clear Register for sram0_busecc_pend (access RW1C)
  [9] RMW0_SRAM_SF_PIPE_BUSECC_ENABLE_CLR — Interrupt Enable Clear Register for rmw0_sram_sf_pipe_busecc_pend (access RW1C)
  [8] RMW0_RMW_TAG_UPDATE_BUSECC_ENABLE_CLR — Interrupt Enable Clear Register for rmw0_rmw_tag_update_busecc_pend (access RW1C)
  [3] EN_MSMC_P3_VBUSP_CFG_SRC_M2M_SRC_BUSECC_DUMMY_ENABLE_CLR — Interrupt Enable Clear Register for en_msmc_p3_vbusp_cfg_src_m2m_src_busecc_dummy_pend (access RW1C)
  [2] EN_MSMC_P3_VBUSP_CFG_SRC_P2M_SRC_BUSECC_DUMMY_ENABLE_CLR — Interrupt Enable Clear Register for en_msmc_p3_vbusp_cfg_src_p2m_src_busecc_dummy_pend (access RW1C)
  [1] EN_MSMC_P3_VBUSP_CFG_SRC_P2M_DST_BUSECC_DUMMY_ENABLE_CLR — Interrupt Enable Clear Register for en_msmc_p3_vbusp_cfg_src_p2m_dst_busecc_dummy_pend (access RW1C)
  [0] EN_MSMC_P3_BUSECC_DUMMY_ENABLE_CLR — Interrupt Enable Clear Register for en_msmc_p3_busecc_dummy_pend (access RW1C)
0xCC MSMC_WRAP_ECC_SEC_ENABLE_CLR_REG3 — Interrupt Enable Clear Register 3
  [11] CLEC_J7ES_CLEC_EDC_CTRL_BUSECC_ENABLE_CLR — Interrupt Enable Clear Register for clec_clec_edc_ctrl_busecc_pend (access RW1C)
  [10] EMIF_0_VSAFE_SI_ENABLE_CLR — Interrupt Enable Clear Register for emif_0_vsafe_si_pend (access RW1C)
  [9] VBUSP_CFG_DSP4_P2P_DST_BUSECC_ENABLE_CLR — Interrupt Enable Clear Register for vbusp_cfg_dsp4_p2p_dst_busecc_pend (access RW1C)
  [8] EMIF1_MST_PIPE_BUSECC_DUMMY_ENABLE_CLR — Interrupt Enable Clear Register for emif1_mst_pipe_busecc_dummy_pend (access RW1C)
  [7] EMIF1_SLV_PIPE_BUSECC_DUMMY_ENABLE_CLR — Interrupt Enable Clear Register for emif1_slv_pipe_busecc_dummy_pend (access RW1C)
  [6] VBUSP_CFG_ECC_AGGR0_P2P_DST_BUSECC_ENABLE_CLR — Interrupt Enable Clear Register for vbusp_cfg_ecc_aggr0_p2p_dst_busecc_pend (access RW1C)
  [5] VBUSP_CFG_ECC_AGGR0_P2P_SRC_BUSECC_DUMMY_ENABLE_CLR — Interrupt Enable Clear Register for vbusp_cfg_ecc_aggr0_p2p_src_busecc_dummy_pend (access RW1C)
  [4] CLEC_SRAM_RAMECC_ENABLE_CLR — Interrupt Enable Clear Register for clec_sram_ramecc_pend (access RW1C)
  [3] DATARAM_BANK3_BUSECC_ENABLE_CLR — Interrupt Enable Clear Register for dataram_bank3_busecc_pend (access RW1C)
  [2] SRAM3_BUSECC_ENABLE_CLR — Interrupt Enable Clear Register for sram3_busecc_pend (access RW1C)
  [1] RMW3_SRAM_SF_PIPE_BUSECC_ENABLE_CLR — Interrupt Enable Clear Register for rmw3_sram_sf_pipe_busecc_pend (access RW1C)
  [0] RMW3_RMW_TAG_UPDATE_BUSECC_ENABLE_CLR — Interrupt Enable Clear Register for rmw3_rmw_tag_update_busecc_pend (access RW1C)
0x13C MSMC_WRAP_ECC_DED_EOI_REG — EOI Register The EOI register is used to re-trigger the pulse interrupt signal to ensure that any nested interrupt events are serviced. The software interrupt handler must write to the EOI register at the end of the current interrupt processing routine, so that new events can re-trigger the pulse interrupt signal again. For level interrupt signals the EOI register is not functional and must not be used.
  [0] EOI_WR — EOI Register (access RW1S)
0x140 MSMC_WRAP_ECC_DED_STATUS_REG0 — Interrupt Status Register 0
  fields as MSMC_WRAP_ECC_SEC_STATUS_REG0
0x144 MSMC_WRAP_ECC_DED_STATUS_REG1 — Interrupt Status Register 1
  fields as MSMC_WRAP_ECC_SEC_STATUS_REG1
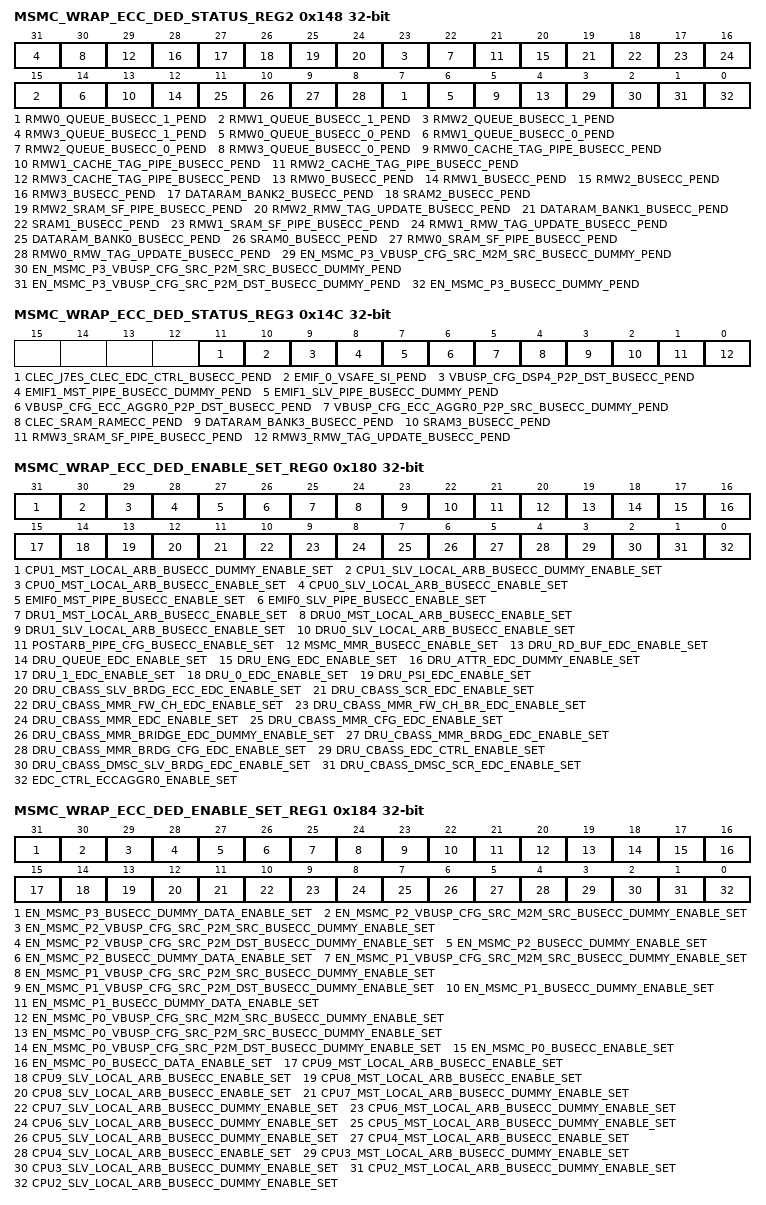
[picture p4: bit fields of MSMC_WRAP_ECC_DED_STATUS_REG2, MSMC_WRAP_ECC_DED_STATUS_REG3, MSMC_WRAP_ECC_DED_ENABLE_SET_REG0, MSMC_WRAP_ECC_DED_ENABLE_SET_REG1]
0x148 MSMC_WRAP_ECC_DED_STATUS_REG2 — Interrupt Status Register 2
  fields as MSMC_WRAP_ECC_SEC_STATUS_REG2
0x14C MSMC_WRAP_ECC_DED_STATUS_REG3 — Interrupt Status Register 3
  fields as MSMC_WRAP_ECC_SEC_STATUS_REG3
0x180 MSMC_WRAP_ECC_DED_ENABLE_SET_REG0 — Interrupt Enable Set Register 0
  fields as MSMC_WRAP_ECC_SEC_ENABLE_SET_REG0
0x184 MSMC_WRAP_ECC_DED_ENABLE_SET_REG1 — Interrupt Enable Set Register 1
  fields as MSMC_WRAP_ECC_SEC_ENABLE_SET_REG1
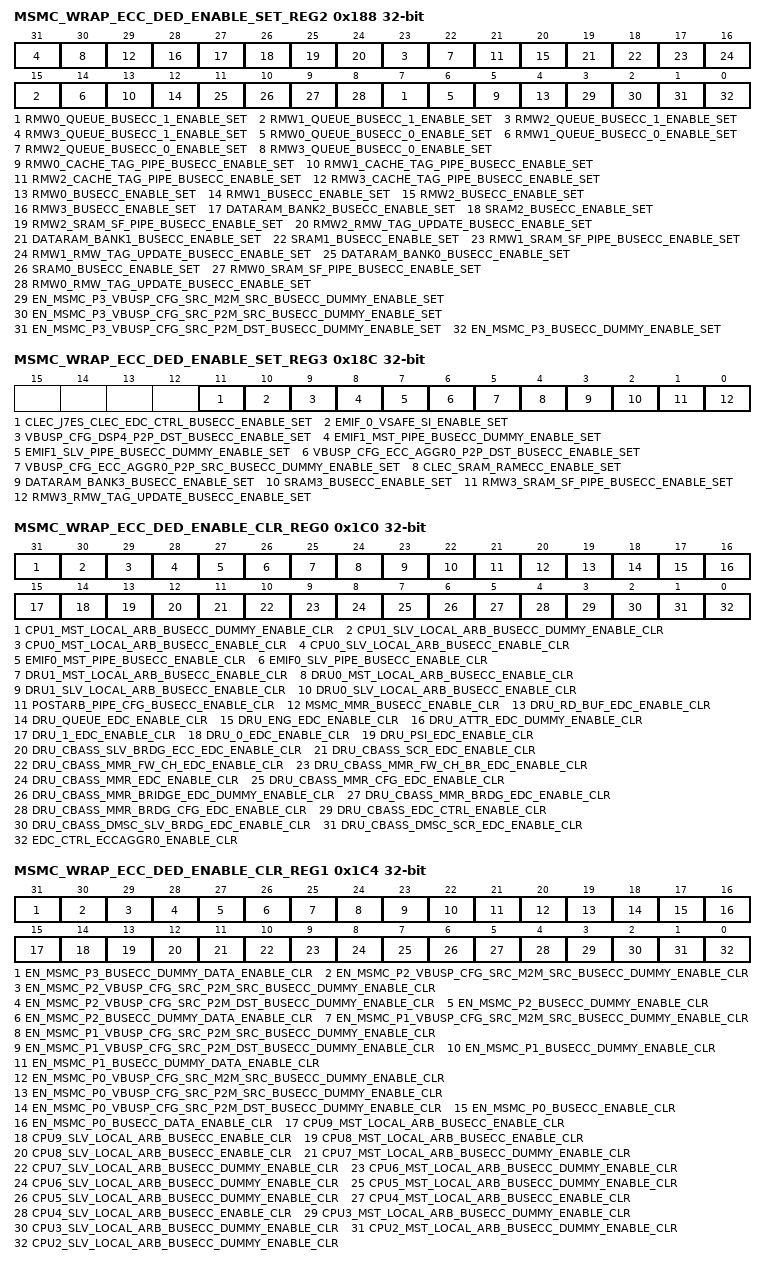
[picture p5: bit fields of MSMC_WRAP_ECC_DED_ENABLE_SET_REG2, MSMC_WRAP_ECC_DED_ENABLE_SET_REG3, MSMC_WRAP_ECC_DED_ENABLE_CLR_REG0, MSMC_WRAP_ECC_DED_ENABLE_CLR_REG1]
0x188 MSMC_WRAP_ECC_DED_ENABLE_SET_REG2 — Interrupt Enable Set Register 2
  fields as MSMC_WRAP_ECC_SEC_ENABLE_SET_REG2
0x18C MSMC_WRAP_ECC_DED_ENABLE_SET_REG3 — Interrupt Enable Set Register 3
  fields as MSMC_WRAP_ECC_SEC_ENABLE_SET_REG3
0x1C0 MSMC_WRAP_ECC_DED_ENABLE_CLR_REG0 — Interrupt Enable Clear Register 0
  fields as MSMC_WRAP_ECC_SEC_ENABLE_CLR_REG0
0x1C4 MSMC_WRAP_ECC_DED_ENABLE_CLR_REG1 — Interrupt Enable Clear Register 1
  fields as MSMC_WRAP_ECC_SEC_ENABLE_CLR_REG1
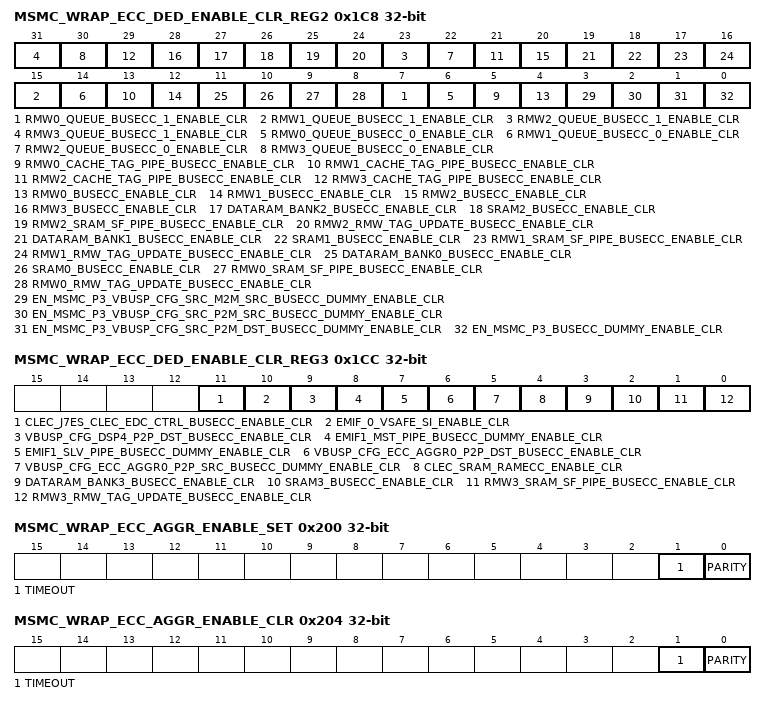
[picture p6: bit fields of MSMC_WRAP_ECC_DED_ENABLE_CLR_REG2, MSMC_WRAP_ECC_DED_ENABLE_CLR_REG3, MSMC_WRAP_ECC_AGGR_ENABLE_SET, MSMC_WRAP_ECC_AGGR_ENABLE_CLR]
0x1C8 MSMC_WRAP_ECC_DED_ENABLE_CLR_REG2 — Interrupt Enable Clear Register 2
  fields as MSMC_WRAP_ECC_SEC_ENABLE_CLR_REG2
0x1CC MSMC_WRAP_ECC_DED_ENABLE_CLR_REG3 — Interrupt Enable Clear Register 3
  fields as MSMC_WRAP_ECC_SEC_ENABLE_CLR_REG3
0x200 MSMC_WRAP_ECC_AGGR_ENABLE_SET — AGGR interrupt enable set Register
  [1] TIMEOUT — interrupt enable set for svbus timeout errors (access RW1S)
  [0] PARITY — interrupt enable set for parity errors (access RW1S)
0x204 MSMC_WRAP_ECC_AGGR_ENABLE_CLR — AGGR interrupt enable clear Register
  [1] TIMEOUT — interrupt enable clear for svbus timeout errors (access RW1C)
  [0] PARITY — interrupt enable clear for parity errors (access RW1C)
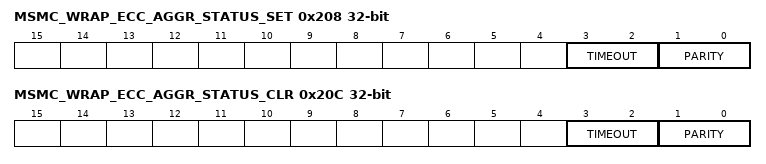
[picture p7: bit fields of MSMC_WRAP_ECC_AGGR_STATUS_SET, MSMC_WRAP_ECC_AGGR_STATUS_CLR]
0x208 MSMC_WRAP_ECC_AGGR_STATUS_SET — AGGR interrupt status set Register
  [3:2] TIMEOUT — interrupt status set for svbus timeout errors (access RWincr)
  [1:0] PARITY — interrupt status set for parity errors (access RWincr)
0x20C MSMC_WRAP_ECC_AGGR_STATUS_CLR — AGGR interrupt status clear Register
  [3:2] TIMEOUT — interrupt status clear for svbus timeout errors (access RWdecr)
  [1:0] PARITY — interrupt status clear for parity errors (access RWdecr)
